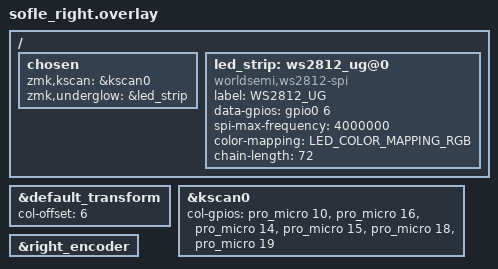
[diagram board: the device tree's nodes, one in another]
#include "sofle.dtsi"

/ {
    chosen {
        /* Define el dispositivo de escaneo y el de los LEDs RGB */
        zmk,kscan = &kscan0;
        zmk,underglow = &led_strip;
    };

    /* Nodo del strip RGB (72 SK6812 Mini-E) */
    led_strip: ws2812_ug@0 {
        compatible = "worldsemi,ws2812-spi";
        label = "WS2812_UG";

        /* ⚠️ Pin de datos: Mikoto 7.2 usa típicamente P0.06, puedes probar P0.15 o P1.08 */
        data-gpios = <&gpio0 6 GPIO_ACTIVE_HIGH>;

        spi-max-frequency = <4000000>;
        color-mapping = <LED_COLOR_MAPPING_RGB>;
        chain-length = <72>;
        status = "okay";
    };
};

/* Ajuste de columnas de la mitad izquierda */
&default_transform {
    col-offset = <6>;
};

/* Pines de columnas del Sofle */
&kscan0 {
    col-gpios =
        <&pro_micro 10 GPIO_ACTIVE_HIGH>,
        <&pro_micro 16 GPIO_ACTIVE_HIGH>,
        <&pro_micro 14 GPIO_ACTIVE_HIGH>,
        <&pro_micro 15 GPIO_ACTIVE_HIGH>,
        <&pro_micro 18 GPIO_ACTIVE_HIGH>,
        <&pro_micro 19 GPIO_ACTIVE_HIGH>;
};

/* Habilita el encoder derecho (solo aplica en left overlay) */
&right_encoder {
    status = "okay";
};
